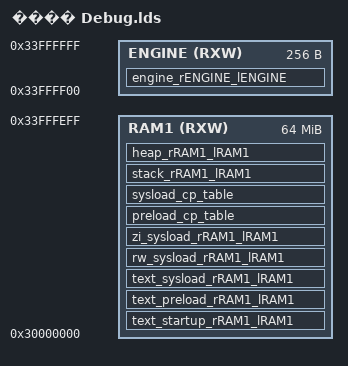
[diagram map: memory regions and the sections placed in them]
/* ld Linker Script - (Debug/Release) */
/* Auto generated by DJYOS lds Editor */
/* Sat Jun 16 00:17:36 CST 2012 */

MEMORY
{
	RAM1(RXW)		: org = 0x30000000, len = 64M-0x100
	ENGINE(RXW)		: org = 0x30000000+64M-0x100, len = 0x100
}

SECTIONS
{
	text_startup_rRAM1_lRAM1 :
	{
		KEEP(* (.isr_vector .isr_vector.*))
		./src/bsp/arch/arm_common/mmucache.o (.data.mmutable)
		./src/bsp/arch/s3c2440/startup/*.o (.text .text.* .rodata .rodata.*)
		./src/bsp/arch/s3c2440/core/*.o (.text .text.* .rodata .rodata.*)
		./src/bsp/arch/arm_common/*.o (.text .text.* .rodata .rodata.*)
		./src/loader/si/pre_loader.o (.text .text.* .rodata .rodata.*)
	}>RAM1 
	
	. = ALIGN(0x08);
	text_preload_rRAM1_lRAM1 :
	{
		KEEP(* (.table.exceptions .table.exceptions.*))
		KEEP(* (.table.vectors .table.vectors.*))
		./src/loader/si/loader.o (.text .text.* .rodata .rodata.*)
		./src/bsp/arch/s3c2440/core/*.o (.text .text.* .rodata .rodata.*)
		./src/djyos/int/int.o (.text .text.* .rodata .rodata.*)
		./src/user/critical/*.o (.text .text.* .rodata .rodata.*)
		./src/bsp/cpu_peripheral/src/gpio.o (.text .text.* .rodata .rodata.*)
		./src/bsp/cpu_peripheral/src/cpu_peri.o (.text .text.* .rodata .rodata.*)
		./src/loader/si/loader.o (.data .data.*)
		./src/bsp/arch/s3c2440/core/*.o  (.data .data.*)
		./src/djyos/int/int.o (.data .data.*)
		./src/user/critical/*.o (.data .data.*)
		./src/bsp/cpu_peripheral/src/gpio.o (.data .data.*)
		./src/bsp/cpu_peripheral/src/cpu_peri.o (.data .data.*)
		./src/bsp/arch/s3c2440/core/*.o (.bss .bss.* COMMON)
		./src/djyos/int/int.o (.bss .bss.* COMMON)
		./src/user/critical/*.o (.bss .bss.* COMMON)
		./src/bsp/cpu_peripheral/src/gpio.o (.bss .bss.* COMMON)
		./src/bsp/cpu_peripheral/src/cpu_peri.o (.bss .bss.* COMMON)
	}>RAM1 
	
	. = ALIGN(0x08);
	text_sysload_rRAM1_lRAM1 :
	{
		* (.text .text.* .rodata .rodata.*)
	}>RAM1 
	
	. = ALIGN(0x08);
	rw_sysload_rRAM1_lRAM1 :
	{
		* (.data .data.*)
	}>RAM1 
	
	. = ALIGN(0x08);
	zi_sysload_rRAM1_lRAM1 (NOLOAD) :
	{
		* (.bss .bss.* COMMON)
	}>RAM1 
	
	. = ALIGN(0x08);
	preload_cp_table :
	{
		preload_copy_table = .;
		LONG(16)
		LONG(1)
		LONG(LOADADDR(text_preload_rRAM1_lRAM1))
		LONG(ADDR(text_preload_rRAM1_lRAM1))
		LONG(SIZEOF(text_preload_rRAM1_lRAM1))
		LONG(1)
	}>RAM1 
	
	. = ALIGN(0x08);
	sysload_cp_table :
	{
		sysload_copy_table = .;
		LONG(16)
		LONG(3)
		LONG(LOADADDR(text_sysload_rRAM1_lRAM1))
		LONG(ADDR(text_sysload_rRAM1_lRAM1))
		LONG(SIZEOF(text_sysload_rRAM1_lRAM1))
		LONG(1)
		LONG(LOADADDR(rw_sysload_rRAM1_lRAM1))
		LONG(ADDR(rw_sysload_rRAM1_lRAM1))
		LONG(SIZEOF(rw_sysload_rRAM1_lRAM1))
		LONG(1)
		LONG(LOADADDR(zi_sysload_rRAM1_lRAM1))
		LONG(ADDR(zi_sysload_rRAM1_lRAM1))
		LONG(SIZEOF(zi_sysload_rRAM1_lRAM1))
		LONG(0)
	}>RAM1 
	
	. = ALIGN(0x08);
	stack_rRAM1_lRAM1 (NOLOAD) :
	{
		usr_bottom = .;
		* (.stack.usr .stack.usr.*)
		usr_top = ALIGN(0x08);
		
		svc_bottom = .;
		* (.stack.svc .stack.svc.*)
		svc_top = ALIGN(0x08);
		
		irq_bottom = .;
		* (.stack.irq .stack.irq.*)
		irq_top = ALIGN(0x08);
		
		fiq_bottom = .;
		* (.stack.fiq .stack.fiq.*)
		fiq_top = ALIGN(0x08);
		
		undef_bottom = .;
		* (.stack.undef .stack.undef.*)
		undef_top = ALIGN(0x08);
		
		abort_bottom = .;
		* (.stack.abort .stack.abort.*)
		abort_top = ALIGN(0x08);
		
	}>RAM1 
	
	. = ALIGN(0x08);
	heap_rRAM1_lRAM1 (NOLOAD) :
	{
		heapsys__bottom = .;
	}>RAM1 
	heapsys__top = 0x30000000+64M-0x100;
	
	. = ALIGN(0x08);
	engine_rENGINE_lENGINE (NOLOAD) :
	{
		engine_irq = .;
		. += 0x04;
		engine_fiq = .;
		. += 0x04;
		engine_undef = .;
		. += 0x04;
		engine_swi = .;
		. += 0x04;
		engine_pabort = .;
		. += 0x04;
		engine_dabort = .;
		. += 0x04;
		engine_reserved = .;
		. += 0x04;
	}>ENGINE 
}
/**** The End ****/
